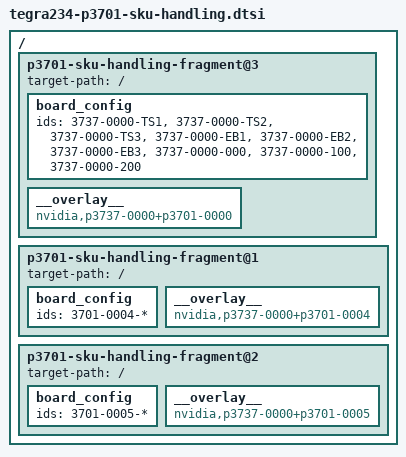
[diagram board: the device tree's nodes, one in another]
// SPDX-License-Identifier: GPL-2.0-only
// Copyright (c) 2023, NVIDIA CORPORATION & AFFILIATES.  All rights reserved.

/ {
	p3701-sku-handling-fragment@3 {
		target-path = "/";
		board_config {
			ids = "3737-0000-TS1","3737-0000-TS2","3737-0000-TS3","3737-0000-EB1","3737-0000-EB2","3737-0000-EB3","3737-0000-000","3737-0000-100","3737-0000-200";
		};
		__overlay__ {
			compatible = "nvidia,p3737-0000+p3701-0000", "nvidia,p3701-0000", "nvidia,tegra234", "nvidia,tegra23x";
		};
	};

	p3701-sku-handling-fragment@1 {
		target-path = "/";
		board_config {
			ids = "3701-0004-*";
		};
		__overlay__ {
			compatible = "nvidia,p3737-0000+p3701-0004", "nvidia,p3701-0004", "nvidia,tegra234", "nvidia,tegra23x";
		};
	};

	p3701-sku-handling-fragment@2 {
		target-path = "/";
		board_config {
			ids = "3701-0005-*";
		};
		__overlay__ {
			compatible = "nvidia,p3737-0000+p3701-0005", "nvidia,p3701-0005", "nvidia,tegra234", "nvidia,tegra23x";
		};
	};

};
